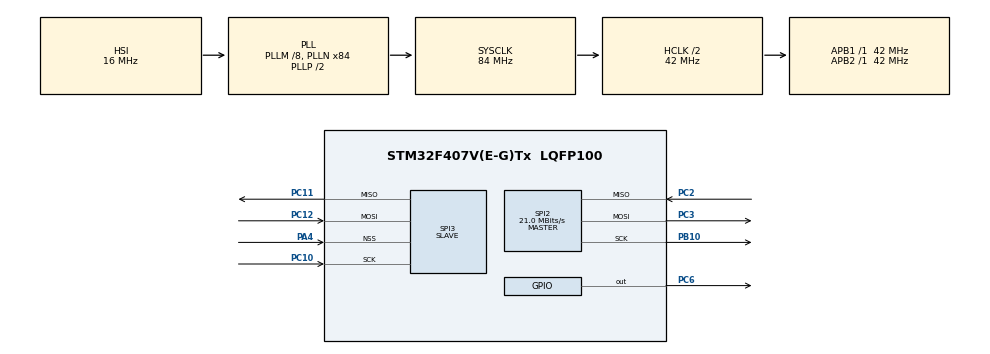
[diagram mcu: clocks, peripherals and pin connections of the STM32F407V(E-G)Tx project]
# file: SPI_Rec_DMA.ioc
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Dma.Request0=SPI3_RX
Dma.SPI3_RX.0.Direction=DMA_PERIPH_TO_MEMORY
Dma.SPI3_RX.0.FIFOMode=DMA_FIFOMODE_DISABLE
Dma.SPI3_RX.0.Instance=DMA1_Stream0
Dma.SPI3_RX.0.MemDataAlignment=DMA_MDATAALIGN_BYTE
Dma.SPI3_RX.0.MemInc=DMA_MINC_ENABLE
Dma.SPI3_RX.0.Mode=DMA_CIRCULAR
Dma.SPI3_RX.0.PeriphDataAlignment=DMA_PDATAALIGN_BYTE
Dma.SPI3_RX.0.PeriphInc=DMA_PINC_DISABLE
Dma.SPI3_RX.0.Priority=DMA_PRIORITY_LOW
Mcu.Family=STM32F4
Mcu.Name=STM32F407V(E-G)Tx
Mcu.Package=LQFP100
NVIC.DMA1_Stream0_IRQn=true\:0\:0\:false\:false\:true\:false
NVIC.PriorityGroup=NVIC_PRIORITYGROUP_4
NVIC.SPI2_IRQn=true\:0\:0\:false\:false\:true\:true
NVIC.SPI3_IRQn=true\:0\:0\:false\:false\:true\:true
PA13.Mode=Serial_Wire
PA13.Signal=SYS_JTMS-SWDIO
PA14.Mode=Serial_Wire
PA14.Signal=SYS_JTCK-SWCLK
PA4.Mode=NSS_Signal_Hard_Input
PA4.Signal=SPI3_NSS
PB10.Mode=Full_Duplex_Master
PB10.Signal=SPI2_SCK
PC10.Mode=Full_Duplex_Slave
PC10.Signal=SPI3_SCK
PC11.Mode=Full_Duplex_Slave
PC11.Signal=SPI3_MISO
PC12.Mode=Full_Duplex_Slave
PC12.Signal=SPI3_MOSI
PC2.Mode=Full_Duplex_Master
PC2.Signal=SPI2_MISO
PC3.Mode=Full_Duplex_Master
PC3.Signal=SPI2_MOSI
PC6.GPIO_Speed=GPIO_SPEED_FREQ_VERY_HIGH
PC6.PinState=GPIO_PIN_SET
PC6.Signal=GPIO_Output
ProjectManager.HeapSize=0x200
ProjectManager.StackSize=0x400
ProjectManager.TargetToolchain=MDK-ARM V5
RCC.48MHZClocksFreq_Value=42000000
RCC.AHBCLKDivider=RCC_SYSCLK_DIV2
RCC.AHBFreq_Value=42000000
RCC.APB1Freq_Value=42000000
RCC.APB1TimFreq_Value=42000000
RCC.APB2Freq_Value=42000000
RCC.APB2TimFreq_Value=42000000
RCC.CortexFreq_Value=42000000
RCC.HCLKFreq_Value=42000000
RCC.HSE_VALUE=25000000
RCC.HSI_VALUE=16000000
RCC.LSE_VALUE=32768
RCC.PLLM=8
RCC.PLLN=84
RCC.SYSCLKFreq_VALUE=84000000
RCC.SYSCLKSource=RCC_SYSCLKSOURCE_PLLCLK
RCC.VCOOutputFreq_Value=168000000
SPI2.BaudRatePrescaler=SPI_BAUDRATEPRESCALER_2
SPI2.CalculateBaudRate=21.0 MBits/s
SPI2.Direction=SPI_DIRECTION_2LINES
SPI2.Mode=SPI_MODE_MASTER
SPI2.VirtualType=VM_MASTER
SPI3.Direction=SPI_DIRECTION_2LINES
SPI3.Mode=SPI_MODE_SLAVE
SPI3.VirtualNSS=VM_NSSHARD
SPI3.VirtualType=VM_SLAVE
board=custom

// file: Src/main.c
/**
  ******************************************************************************
  * @file           : main.c
  * @brief          : Main program body
  ******************************************************************************
  ** This notice applies to any and all portions of this file
  * that are not between comment pairs USER CODE BEGIN and
  * USER CODE END. Other portions of this file, whether
  * inserted by the user or by software development tools
  * are owned by their respective copyright owners.
  *
  * COPYRIGHT(c) 2018 STMicroelectronics
  *
  * Redistribution and use in source and binary forms, with or without modification,
  * are permitted provided that the following conditions are met:
  *   1. Redistributions of source code must retain the above copyright notice,
  *      this list of conditions and the following disclaimer.
  *   2. Redistributions in binary form must reproduce the above copyright notice,
  *      this list of conditions and the following disclaimer in the documentation
  *      and/or other materials provided with the distribution.
  *   3. Neither the name of STMicroelectronics nor the names of its contributors
  *      may be used to endorse or promote products derived from this software
  *      without specific prior written permission.
  *
  * THIS SOFTWARE IS PROVIDED BY THE COPYRIGHT HOLDERS AND CONTRIBUTORS "AS IS"
  * AND ANY EXPRESS OR IMPLIED WARRANTIES, INCLUDING, BUT NOT LIMITED TO, THE
  * IMPLIED WARRANTIES OF MERCHANTABILITY AND FITNESS FOR A PARTICULAR PURPOSE ARE
  * DISCLAIMED. IN NO EVENT SHALL THE COPYRIGHT HOLDER OR CONTRIBUTORS BE LIABLE
  * FOR ANY DIRECT, INDIRECT, INCIDENTAL, SPECIAL, EXEMPLARY, OR CONSEQUENTIAL
  * DAMAGES (INCLUDING, BUT NOT LIMITED TO, PROCUREMENT OF SUBSTITUTE GOODS OR
  * SERVICES; LOSS OF USE, DATA, OR PROFITS; OR BUSINESS INTERRUPTION) HOWEVER
  * CAUSED AND ON ANY THEORY OF LIABILITY, WHETHER IN CONTRACT, STRICT LIABILITY,
  * OR TORT (INCLUDING NEGLIGENCE OR OTHERWISE) ARISING IN ANY WAY OUT OF THE USE
  * OF THIS SOFTWARE, EVEN IF ADVISED OF THE POSSIBILITY OF SUCH DAMAGE.
  *
  ******************************************************************************
  */
#include "main.h"
#include "stm32f4xx_hal.h"

/* USER CODE BEGIN Includes */
/*
SPI2-master
SPI3-slave -DMA
PC2(SPI2 MISO) -PC11(SPI3 MISO)
PC3(SPI2 MOSI) -PC12(SPI3 MOSI)
PB10(SPI2 Clk) -PC10(SPI3 Clk)
PC6(SPI2 -software control) - PA4(SPI3 Hardware control)
*/

#define spi_enable  	HAL_GPIO_WritePin(GPIOC,GPIO_PIN_6,GPIO_PIN_RESET)
#define spi_disable 	HAL_GPIO_WritePin(GPIOC,GPIO_PIN_6,GPIO_PIN_SET)

/* USER CODE END Includes */

SPI_HandleTypeDef hspi2;
SPI_HandleTypeDef hspi3;
DMA_HandleTypeDef hdma_spi3_rx;

/* USER CODE BEGIN PV */
/* Private variables ---------------------------------------------------------*/
uint8_t sendata =32, receive_data =0;

/* USER CODE END PV */

void SystemClock_Config(void);
static void MX_GPIO_Init(void);
static void MX_DMA_Init(void);
static void MX_SPI2_Init(void);
static void MX_SPI3_Init(void);

/* USER CODE BEGIN PFP */
/* Private function prototypes -----------------------------------------------*/

/* USER CODE END PFP */

int main(void)
{

  /* MCU Configuration----------------------------------------------------------*/

  /* Reset of all peripherals, Initializes the Flash interface and the Systick. */
  HAL_Init();

  /* Configure the system clock */
  SystemClock_Config();

  /* Initialize all configured peripherals */
  MX_GPIO_Init();
  MX_DMA_Init();
  MX_SPI2_Init();
  MX_SPI3_Init();
  /* USER CODE BEGIN 2 */
	HAL_SPI_Receive_DMA(&hspi3,&receive_data,1);

  /* USER CODE END 2 */

  /* Infinite loop */
  /* USER CODE BEGIN WHILE */
  while (1)
  {
		spi_enable;
		HAL_SPI_Transmit_IT(&hspi2,&sendata,1);
		HAL_Delay(1000);
		sendata++;

  /* USER CODE END WHILE */

  }

}

void SystemClock_Config(void)
{

  RCC_OscInitTypeDef RCC_OscInitStruct;
  RCC_ClkInitTypeDef RCC_ClkInitStruct;

    /**Configure the main internal regulator output voltage
    */
  __HAL_RCC_PWR_CLK_ENABLE();

  __HAL_PWR_VOLTAGESCALING_CONFIG(PWR_REGULATOR_VOLTAGE_SCALE1);

    /**Initializes the CPU, AHB and APB busses clocks
    */
  RCC_OscInitStruct.OscillatorType = RCC_OSCILLATORTYPE_HSI;
  RCC_OscInitStruct.HSIState = RCC_HSI_ON;
  RCC_OscInitStruct.HSICalibrationValue = 16;
  RCC_OscInitStruct.PLL.PLLState = RCC_PLL_ON;
  RCC_OscInitStruct.PLL.PLLSource = RCC_PLLSOURCE_HSI;
  RCC_OscInitStruct.PLL.PLLM = 8;
  RCC_OscInitStruct.PLL.PLLN = 84;
  RCC_OscInitStruct.PLL.PLLP = RCC_PLLP_DIV2;
  RCC_OscInitStruct.PLL.PLLQ = 4;
  if (HAL_RCC_OscConfig(&RCC_OscInitStruct) != HAL_OK)
  {
    _Error_Handler(__FILE__, __LINE__);
  }

    /**Initializes the CPU, AHB and APB busses clocks
    */
  RCC_ClkInitStruct.ClockType = RCC_CLOCKTYPE_HCLK|RCC_CLOCKTYPE_SYSCLK
                              |RCC_CLOCKTYPE_PCLK1|RCC_CLOCKTYPE_PCLK2;
  RCC_ClkInitStruct.SYSCLKSource = RCC_SYSCLKSOURCE_PLLCLK;
  RCC_ClkInitStruct.AHBCLKDivider = RCC_SYSCLK_DIV2;
  RCC_ClkInitStruct.APB1CLKDivider = RCC_HCLK_DIV1;
  RCC_ClkInitStruct.APB2CLKDivider = RCC_HCLK_DIV1;

  if (HAL_RCC_ClockConfig(&RCC_ClkInitStruct, FLASH_LATENCY_1) != HAL_OK)
  {
    _Error_Handler(__FILE__, __LINE__);
  }

    /**Configure the Systick interrupt time
    */
  HAL_SYSTICK_Config(HAL_RCC_GetHCLKFreq()/1000);

    /**Configure the Systick
    */
  HAL_SYSTICK_CLKSourceConfig(SYSTICK_CLKSOURCE_HCLK);

  /* SysTick_IRQn interrupt configuration */
  HAL_NVIC_SetPriority(SysTick_IRQn, 0, 0);
}

/* SPI2 init function */
static void MX_SPI2_Init(void)
{

  /* SPI2 parameter configuration*/
  hspi2.Instance = SPI2;
  hspi2.Init.Mode = SPI_MODE_MASTER;
  hspi2.Init.Direction = SPI_DIRECTION_2LINES;
  hspi2.Init.DataSize = SPI_DATASIZE_8BIT;
  hspi2.Init.CLKPolarity = SPI_POLARITY_LOW;
  hspi2.Init.CLKPhase = SPI_PHASE_1EDGE;
  hspi2.Init.NSS = SPI_NSS_SOFT;
  hspi2.Init.BaudRatePrescaler = SPI_BAUDRATEPRESCALER_2;
  hspi2.Init.FirstBit = SPI_FIRSTBIT_MSB;
  hspi2.Init.TIMode = SPI_TIMODE_DISABLE;
  hspi2.Init.CRCCalculation = SPI_CRCCALCULATION_DISABLE;
  hspi2.Init.CRCPolynomial = 10;
  if (HAL_SPI_Init(&hspi2) != HAL_OK)
  {
    _Error_Handler(__FILE__, __LINE__);
  }

}

/* SPI3 init function */
static void MX_SPI3_Init(void)
{

  /* SPI3 parameter configuration*/
  hspi3.Instance = SPI3;
  hspi3.Init.Mode = SPI_MODE_SLAVE;
  hspi3.Init.Direction = SPI_DIRECTION_2LINES;
  hspi3.Init.DataSize = SPI_DATASIZE_8BIT;
  hspi3.Init.CLKPolarity = SPI_POLARITY_LOW;
  hspi3.Init.CLKPhase = SPI_PHASE_1EDGE;
  hspi3.Init.NSS = SPI_NSS_HARD_INPUT;
  hspi3.Init.FirstBit = SPI_FIRSTBIT_MSB;
  hspi3.Init.TIMode = SPI_TIMODE_DISABLE;
  hspi3.Init.CRCCalculation = SPI_CRCCALCULATION_DISABLE;
  hspi3.Init.CRCPolynomial = 10;
  if (HAL_SPI_Init(&hspi3) != HAL_OK)
  {
    _Error_Handler(__FILE__, __LINE__);
  }

}

static void MX_DMA_Init(void)
{
  /* DMA controller clock enable */
  __HAL_RCC_DMA1_CLK_ENABLE();

  /* DMA interrupt init */
  /* DMA1_Stream0_IRQn interrupt configuration */
  HAL_NVIC_SetPriority(DMA1_Stream0_IRQn, 0, 0);
  HAL_NVIC_EnableIRQ(DMA1_Stream0_IRQn);

}

/** Configure pins as
        * Analog
        * Input
        * Output
        * EVENT_OUT
        * EXTI
*/
static void MX_GPIO_Init(void)
{

  GPIO_InitTypeDef GPIO_InitStruct;

  /* GPIO Ports Clock Enable */
  __HAL_RCC_GPIOC_CLK_ENABLE();
  __HAL_RCC_GPIOA_CLK_ENABLE();
  __HAL_RCC_GPIOB_CLK_ENABLE();

  /*Configure GPIO pin Output Level */
  HAL_GPIO_WritePin(GPIOC, GPIO_PIN_6, GPIO_PIN_SET);

  /*Configure GPIO pin : PC6 */
  GPIO_InitStruct.Pin = GPIO_PIN_6;
  GPIO_InitStruct.Mode = GPIO_MODE_OUTPUT_PP;
  GPIO_InitStruct.Pull = GPIO_NOPULL;
  GPIO_InitStruct.Speed = GPIO_SPEED_FREQ_VERY_HIGH;
  HAL_GPIO_Init(GPIOC, &GPIO_InitStruct);

}

/* USER CODE BEGIN 4 */
void HAL_SPI_TxCpltCallback(SPI_HandleTypeDef *hspi)
{
		if(hspi->Instance==hspi2.Instance) // Truyen xong disable
		{
			spi_disable;
		}

}

/* USER CODE END 4 */

void _Error_Handler(char *file, int line)
{
  while(1)
  {
  }
}

/************************ (C) COPYRIGHT STMicroelectronics *****END OF FILE****/
